VERSION ""

NS_ :

BS_:

BU_: IPC GWM BCM
VAL_TABLE_ Preset_6_Bank_Rq_ValueTable 7 "Preset_6_Seven" 6 "Preset_6_Six" 5 "Preset_6_Five" 4 "Preset_6_Four" 3 "Preset_6_Three" 2 "Preset_6_Two" 1 "Preset_6_One" 0 "Preset_6_None" ;
VAL_TABLE_ Ahb_Dsply_ValueTable 1 "On" 0 "Off" ;
VAL_TABLE_ TP_Data_Rq_ValueTable 15 "Data_15" 14 "Data_14" 13 "Data_13" 12 "Data_12" 11 "Data_11" 10 "Data_10" 9 "Data_9" 8 "Data_8" 7 "Data_7" 6 "Data_6" 5 "Data_5" 4 "Data_4" 3 "Data_3" 2 "Data_2" 1 "Data_1" 0 "Unused" ;
VAL_TABLE_ TA_Data_Rq_ValueTableDLC2 3 "Not_Used" 2 "Available" 1 "Unavailable" 0 "None" ;
VAL_TABLE_ Menu_scrn_1_Data 3 "Not_Used" 2 "On" 1 "Off" 0 "No_Menu" ;
VAL_TABLE_ Artst_Name_1_Rq_ValueTable 7 "Artist7" 6 "Artist6" 5 "Artist5" 4 "Artist4" 3 "Artist3" 2 "Artist2" 1 "Artist1" 0 "Not_Used" ;
VAL_TABLE_ Radio_Txt_1_Rq_ValueTable 15 "Message15" 14 "Message14" 13 "Message13" 12 "Message12" 11 "Message11" 10 "Message10" 9 "Message9" 8 "Message8" 7 "Message7" 6 "Message6" 5 "Message5" 4 "Message4" 3 "Message3" 2 "Message2" 1 "Message1" 0 "No_Message" ;
VAL_TABLE_ Ignition_Status_ValueTable 1 "RUN" 0 "Off" ;
VAL_TABLE_ CRD_Msg_Txt_Rq_Dsply_ValueTable 1 "On" 0 "Off" ;
VAL_TABLE_ Preset_12_Bank_Rq_ValueTable 15 "Not_Used3" 14 "Not_Used2" 13 "Not_Used1" 12 "Preset_12_Twelve" 11 "Preset_12_Eleven" 10 "Preset_12_Ten" 9 "Preset_12_Nine" 8 "Preset_12_Eight" 7 "Preset_12_Seven" 6 "Preset_12_Six" 5 "Preset_12_Five" 4 "Preset_12_Four" 3 "Preset_12_Three" 2 "Preset_12_Two" 1 "Preset_12_One" 0 "Preset_12_None" ;
VAL_TABLE_ Actv_Live_2_Rq_ValueTable 3 "Disabled" 2 "On" 1 "Off" 0 "Unavailable" ;
VAL_TABLE_ Actv_Live_1_Rq_ValueTable 3 "Disabled" 2 "On" 1 "Off" 0 "Unavailable" ;
VAL_TABLE_ Indictr_Rgt_Dsply 1 "on" 0 "off" ;
VAL_TABLE_ Indictr_Lft_Dsply_ValueTable 1 "on" 0 "off" ;
VAL_TABLE_ HMI_MID_Sgnl_3_Rq_ValueTable 15 "Fifteen_Sig_3" 14 "Fourteen_Sig_3" 13 "Thirteen_Sig_3" 12 "Twelve_Sig_3" 11 "Eleven_Sig_3" 10 "Ten_Sig_3" 9 "Nine_Sig_3" 8 "Eight_Sig_3" 7 "Seven_Sig_3" 6 "Six_Sig_3" 5 "Five_Sig_3" 4 "Four_Sig_3" 3 "Three_Sig_3" 2 "Two_Sig_3" 1 "One_Sig_3" 0 "Zero_Sig_3" ;
VAL_TABLE_ HMI_MID_Sgnl_2_Rq_Valuetable 15 "Fifteen_Sig_2" 14 "Fourteen_Sig_2" 13 "Thirteen_Sig_2" 12 "Twelve_Sig_2" 11 "Eleven_Sig_2" 10 "Ten_Sig_2" 9 "Nine_Sig_2" 8 "Eight_Sig_2" 7 "Seven_Sig_2" 6 "Six_Sig_2" 5 "Five_Sig_2" 4 "Four_Sig_2" 3 "Three_Sig_2" 2 "Two_Sig_2" 1 "One_Sig_2" 0 "Zero_Sig_2" ;
VAL_TABLE_ HMI_MID_Sgnl_1_Rq_Valuetable 15 "Fifteen_Sig_1" 14 "Fourteen_Sig_1" 13 "Thirteen_Sig_1" 12 "Twelve_Sig_1" 11 "Eleven_Sig_1" 10 "Ten_Sig_1" 9 "Nine_Sig_1" 8 "Eight_Sig_1" 7 "Seven_Sig_1" 6 "Six_Sig_1" 5 "Five_Sig_1" 4 "Four_Sig_1" 3 "Three_Sig_1" 2 "Two_Sig_1" 1 "One_Sig_1" 0 "Zero_Sig_1" ;

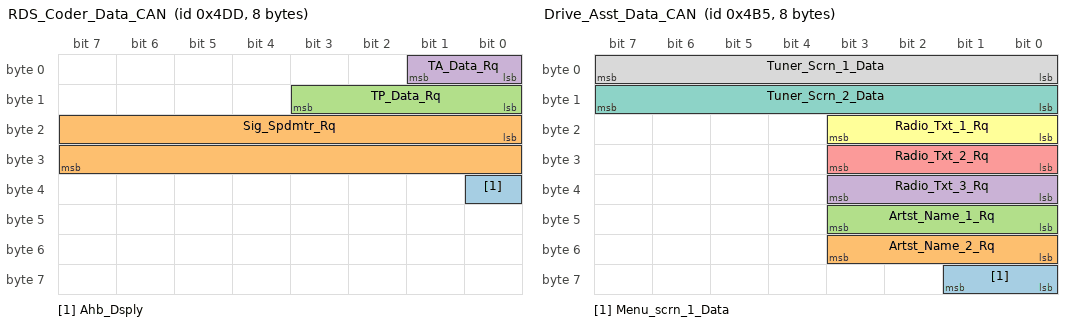
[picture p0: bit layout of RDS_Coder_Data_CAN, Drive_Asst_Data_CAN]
BO_ 1245 RDS_Coder_Data_CAN: 8 GWM
 SG_ Ahb_Dsply : 32|1@1+ (1,0) [0|1] ""  IPC
 SG_ Sig_Spdmtr_Rq : 16|16@1+ (1,0) [0|240] "SED"  IPC
 SG_ TP_Data_Rq : 8|4@1+ (1,0) [0|15] "SED"  IPC
 SG_ TA_Data_Rq : 0|2@1+ (1,0) [0|3] ""  IPC

BO_ 1205 Drive_Asst_Data_CAN: 8 BCM
 SG_ Menu_scrn_1_Data : 56|2@1+ (1,0) [0|3] "SED"  IPC
 SG_ Artst_Name_2_Rq : 48|4@1+ (1,0) [0|7] ""  IPC
 SG_ Artst_Name_1_Rq : 40|4@1+ (1,0) [0|7] ""  IPC
 SG_ Radio_Txt_3_Rq : 32|4@1+ (1,0) [0|15] ""  IPC
 SG_ Radio_Txt_2_Rq : 24|4@1+ (1,0) [0|15] "SED"  IPC
 SG_ Radio_Txt_1_Rq : 16|4@1+ (1,0) [0|15] "SED"  IPC
 SG_ Tuner_Scrn_2_Data : 8|8@1+ (1,0) [0|255] "Hz"  IPC
 SG_ Tuner_Scrn_1_Data : 0|8@1+ (1,0) [0|255] "Hz"  IPC

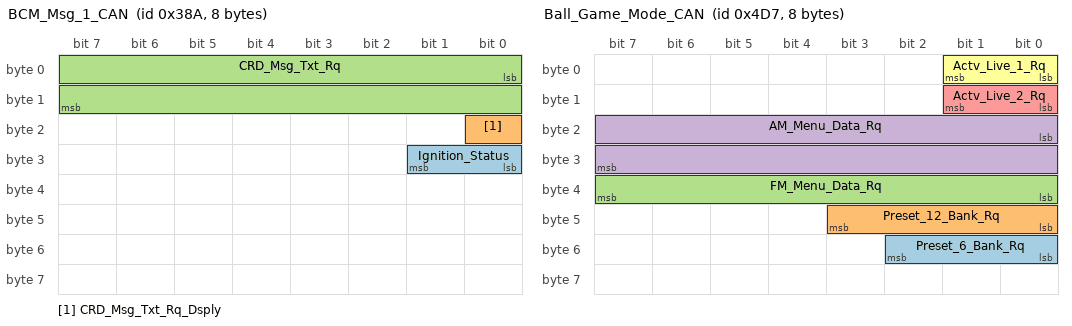
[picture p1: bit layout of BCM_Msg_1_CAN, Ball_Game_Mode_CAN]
BO_ 906 BCM_Msg_1_CAN: 8 BCM
 SG_ Ignition_Status : 24|2@1+ (1,0) [0|3] ""  IPC
 SG_ CRD_Msg_Txt_Rq_Dsply : 16|1@1+ (1,0) [0|1] "SED"  IPC
 SG_ CRD_Msg_Txt_Rq : 0|16@1+ (1,0) [0|65535] ""  IPC

BO_ 1239 Ball_Game_Mode_CAN: 8 GWM
 SG_ Preset_6_Bank_Rq : 48|3@1+ (1,0) [0|7] "SED"  IPC
 SG_ Preset_12_Bank_Rq : 40|4@1+ (1,0) [0|15] "SED"  IPC
 SG_ FM_Menu_Data_Rq : 32|8@1+ (1,0) [0|255] "SED"  IPC
 SG_ AM_Menu_Data_Rq : 16|16@1+ (1,0) [0|65535] ""  IPC
 SG_ Actv_Live_2_Rq : 8|2@1+ (1,0) [0|3] "SED"  IPC
 SG_ Actv_Live_1_Rq : 0|2@1+ (1,0) [0|3] "SED"  IPC

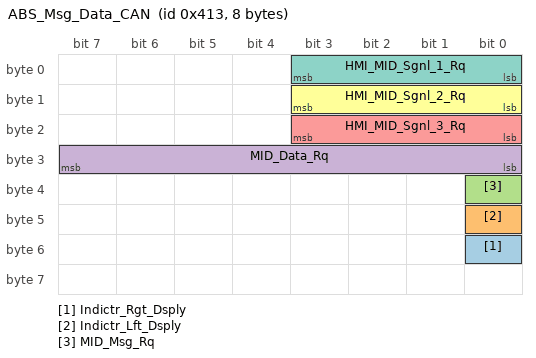
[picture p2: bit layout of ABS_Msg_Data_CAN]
BO_ 1043 ABS_Msg_Data_CAN: 8 GWM
 SG_ Indictr_Rgt_Dsply : 48|1@1+ (1,0) [0|1] ""  IPC
 SG_ Indictr_Lft_Dsply : 40|1@1+ (1,0) [0|1] ""  IPC
 SG_ MID_Msg_Rq : 32|1@1+ (1,0) [0|1] "SED"  IPC
 SG_ MID_Data_Rq : 24|8@1+ (1,0) [0|255] "range"  IPC
 SG_ HMI_MID_Sgnl_3_Rq : 16|4@1+ (1,0) [0|15] "SED"  IPC
 SG_ HMI_MID_Sgnl_2_Rq : 8|4@1+ (1,0) [0|15] "SED"  IPC
 SG_ HMI_MID_Sgnl_1_Rq : 0|4@1+ (1,0) [0|15] "SED"  IPC

BA_DEF_ BO_  "GenMsgCycleTime" INT 0 20000;
BA_DEF_ BO_  "GenMsgSendType" ENUM  "NA","Event","EventPeriodic","FixedPeriodic";
BA_DEF_DEF_  "GenMsgCycleTime" 0;
BA_DEF_DEF_  "GenMsgSendType" "NA";
BA_ "GenMsgSendType" BO_ 1245 1;
BA_ "GenMsgCycleTime" BO_ 1205 1000;
BA_ "GenMsgSendType" BO_ 1205 2;
BA_ "GenMsgCycleTime" BO_ 906 100;
BA_ "GenMsgSendType" BO_ 906 3;
BA_ "GenMsgCycleTime" BO_ 1239 50;
BA_ "GenMsgSendType" BO_ 1239 3;
BA_ "GenMsgCycleTime" BO_ 1043 1500;
BA_ "GenMsgSendType" BO_ 1043 2;
VAL_ 1245 Ahb_Dsply 1 "On" 0 "Off" ;
VAL_ 1245 TP_Data_Rq 15 "Data_15" 14 "Data_14" 13 "Data_13" 12 "Data_12" 11 "Data_11" 10 "Data_10" 9 "Data_9" 8 "Data_8" 7 "Data_7" 6 "Data_6" 5 "Data_5" 4 "Data_4" 3 "Data_3" 2 "Data_2" 1 "Data_1" 0 "Unused" ;
VAL_ 1245 TA_Data_Rq 3 "Not_Used" 2 "Available" 1 "Unavailable" 0 "None" ;
VAL_ 1205 Menu_scrn_1_Data 3 "Not_Used" 2 "On" 1 "Off" 0 "No_Menu" ;
VAL_ 1205 Artst_Name_2_Rq 7 "Artist7" 6 "Artist6" 5 "Artist5" 4 "Artist4" 3 "Artist3" 2 "Artist2" 1 "Artist1" 0 "Not_Used" ;
VAL_ 1205 Artst_Name_1_Rq 7 "Artist7" 6 "Artist6" 5 "Artist5" 4 "Artist4" 3 "Artist3" 2 "Artist2" 1 "Artist1" 0 "Not_Used" ;
VAL_ 1205 Radio_Txt_3_Rq 15 "Message15" 14 "Message14" 13 "Message13" 12 "Message12" 11 "Message11" 10 "Message10" 9 "Message9" 8 "Message8" 7 "Message7" 6 "Message6" 5 "Message5" 4 "Message4" 3 "Message3" 2 "Message2" 1 "Message1" 0 "No_Message" ;
VAL_ 1205 Radio_Txt_2_Rq 15 "Message15" 14 "Message14" 13 "Message13" 12 "Message12" 11 "Message11" 10 "Message10" 9 "Message9" 8 "Message8" 7 "Message7" 6 "Message6" 5 "Message5" 4 "Message4" 3 "Message3" 2 "Message2" 1 "Message1" 0 "No_Message" ;
VAL_ 1205 Radio_Txt_1_Rq 15 "Message15" 14 "Message14" 13 "Message13" 12 "Message12" 11 "Message11" 10 "Message10" 9 "Message9" 8 "Message8" 7 "Message7" 6 "Message6" 5 "Message5" 4 "Message4" 3 "Message3" 2 "Message2" 1 "Message1" 0 "No_Message" ;
VAL_ 906 Ignition_Status 1 "RUN" 0 "Off" ;
VAL_ 906 CRD_Msg_Txt_Rq_Dsply 1 "On" 0 "Off" ;
VAL_ 1239 Preset_6_Bank_Rq 7 "Preset_6_Seven" 6 "Preset_6_Six" 5 "Preset_6_Five" 4 "Preset_6_Four" 3 "Preset_6_Three" 2 "Preset_6_Two" 1 "Preset_6_One" 0 "Preset_6_None" ;
VAL_ 1239 Preset_12_Bank_Rq 15 "Not_Used3" 14 "Not_Used2" 13 "Not_Used1" 12 "Preset_12_Twelve" 11 "Preset_12_Eleven" 10 "Preset_12_Ten" 9 "Preset_12_Nine" 8 "Preset_12_Eight" 7 "Preset_12_Seven" 6 "Preset_12_Six" 5 "Preset_12_Five" 4 "Preset_12_Four" 3 "Preset_12_Three" 2 "Preset_12_Two" 1 "Preset_12_One" 0 "Preset_12_None" ;
VAL_ 1239 Actv_Live_2_Rq 3 "Disabled" 2 "On" 1 "Off" 0 "Unavailable" ;
VAL_ 1239 Actv_Live_1_Rq 3 "Disabled" 2 "On" 1 "Off" 0 "Unavailable" ;
VAL_ 1043 Indictr_Rgt_Dsply 1 "on" 0 "off" ;
VAL_ 1043 Indictr_Lft_Dsply 1 "on" 0 "off" ;
VAL_ 1043 HMI_MID_Sgnl_3_Rq 15 "Fifteen_Sig_3" 14 "Fourteen_Sig_3" 13 "Thirteen_Sig_3" 12 "Twelve_Sig_3" 11 "Eleven_Sig_3" 10 "Ten_Sig_3" 9 "Nine_Sig_3" 8 "Eight_Sig_3" 7 "Seven_Sig_3" 6 "Six_Sig_3" 5 "Five_Sig_3" 4 "Four_Sig_3" 3 "Three_Sig_3" 2 "Two_Sig_3" 1 "One_Sig_3" 0 "Zero_Sig_3" ;
VAL_ 1043 HMI_MID_Sgnl_2_Rq 15 "Fifteen_Sig_2" 14 "Fourteen_Sig_2" 13 "Thirteen_Sig_2" 12 "Twelve_Sig_2" 11 "Eleven_Sig_2" 10 "Ten_Sig_2" 9 "Nine_Sig_2" 8 "Eight_Sig_2" 7 "Seven_Sig_2" 6 "Six_Sig_2" 5 "Five_Sig_2" 4 "Four_Sig_2" 3 "Three_Sig_2" 2 "Two_Sig_2" 1 "One_Sig_2" 0 "Zero_Sig_2" ;
VAL_ 1043 HMI_MID_Sgnl_1_Rq 15 "Fifteen_Sig_1" 14 "Fourteen_Sig_1" 13 "Thirteen_Sig_1" 12 "Twelve_Sig_1" 11 "Eleven_Sig_1" 10 "Ten_Sig_1" 9 "Nine_Sig_1" 8 "Eight_Sig_1" 7 "Seven_Sig_1" 6 "Six_Sig_1" 5 "Five_Sig_1" 4 "Four_Sig_1" 3 "Three_Sig_1" 2 "Two_Sig_1" 1 "One_Sig_1" 0 "Zero_Sig_1" ;
